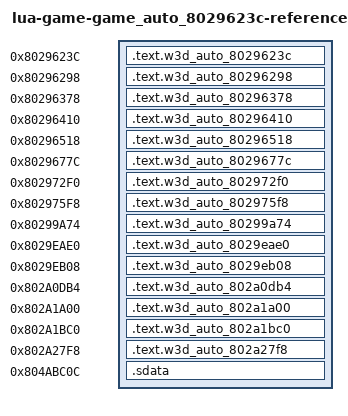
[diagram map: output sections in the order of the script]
/* Generated reference-only placements. All bodies are source-built. */
OUTPUT_FORMAT("elf32-powerpc")
OUTPUT_ARCH(powerpc)
ENTRY(w3d_auto_8029623c)
_SDA_BASE_ = 0x804b2540;
_SDA2_BASE_ = 0x804c2540;
fn_8015F5A0 = 0x8015f5a0;
fn_8015FD1C = 0x8015fd1c;
fn_80162024 = 0x80162024;
fn_80173F88 = 0x80173f88;
fn_80178D1C = 0x80178d1c;
fn_802958D8 = 0x802958d8;
fn_80295CEC = 0x80295cec;
fn_80296498 = 0x80296498;
fn_80296598 = 0x80296598;
fn_8029D07C = 0x8029d07c;
fn_8029D578 = 0x8029d578;
fn_8029E194 = 0x8029e194;
fn_802A0C48 = 0x802a0c48;
fn_802A21EC = 0x802a21ec;
fn_802B15E0 = 0x802b15e0;
fn_802B1BD0 = 0x802b1bd0;
fn_802B1F98 = 0x802b1f98;
SECTIONS {
  .text.w3d_auto_8029623c 0x8029623c : { *(.text.w3d_auto_8029623c) }
  .text.w3d_auto_80296298 0x80296298 : { *(.text.w3d_auto_80296298) }
  .text.w3d_auto_80296378 0x80296378 : { *(.text.w3d_auto_80296378) }
  .text.w3d_auto_80296410 0x80296410 : { *(.text.w3d_auto_80296410) }
  .text.w3d_auto_80296518 0x80296518 : { *(.text.w3d_auto_80296518) }
  .text.w3d_auto_8029677c 0x8029677c : { *(.text.w3d_auto_8029677c) }
  .text.w3d_auto_802972f0 0x802972f0 : { *(.text.w3d_auto_802972f0) }
  .text.w3d_auto_802975f8 0x802975f8 : { *(.text.w3d_auto_802975f8) }
  .text.w3d_auto_80299a74 0x80299a74 : { *(.text.w3d_auto_80299a74) }
  .text.w3d_auto_8029eae0 0x8029eae0 : { *(.text.w3d_auto_8029eae0) }
  .text.w3d_auto_8029eb08 0x8029eb08 : { *(.text.w3d_auto_8029eb08) }
  .text.w3d_auto_802a0db4 0x802a0db4 : { *(.text.w3d_auto_802a0db4) }
  .text.w3d_auto_802a1a00 0x802a1a00 : { *(.text.w3d_auto_802a1a00) }
  .text.w3d_auto_802a1bc0 0x802a1bc0 : { *(.text.w3d_auto_802a1bc0) }
  .text.w3d_auto_802a27f8 0x802a27f8 : { *(.text.w3d_auto_802a27f8) }
  .sdata 0x804abc0c (NOLOAD) : {
    . = 0x0; lbl_804ABC0C = .;
    . = 0x5190; lbl_804B0D9C = .;
    . = 0x5198; lbl_804B0DA4 = .;
    . = 0x51a0; lbl_804B0DAC = .;
    . = 0x51a8; lbl_804B0DB4 = .;
    . = 0x51b0; lbl_804B0DBC = .;
    . = 0x51b8; lbl_804B0DC4 = .;
    . = 0x51c0; lbl_804B0DCC = .;
    . = 0x51c8; lbl_804B0DD4 = .;
    . = 0x51d0; lbl_804B0DDC = .;
    . = 0x51d8; lbl_804B0DE4 = .;
    . = 0x51e0; lbl_804B0DEC = .;
    . = 0x51e8; lbl_804B0DF4 = .;
    . = 0x51f0; lbl_804B0DFC = .;
    . = 0x51f8; lbl_804B0E04 = .;
    . = 0x5200; lbl_804B0E0C = .;
    . = 0x5208; lbl_804B0E14 = .;
    . = 0x5210; lbl_804B0E1C = .;
    . = 0x5218; lbl_804B0E24 = .;
    . = 0x5220; lbl_804B0E2C = .;
    . = 0x5228; lbl_804B0E34 = .;
    . = 0x5230; lbl_804B0E3C = .;
    . = 0x5238; lbl_804B0E44 = .;
    . = 0x5240; lbl_804B0E4C = .;
    . += 1; }
  /DISCARD/ : { *(.text*) *(.rodata*) *(.data*) *(.bss*) *(.sdata*) *(.sbss*) *(.comment) }
}
